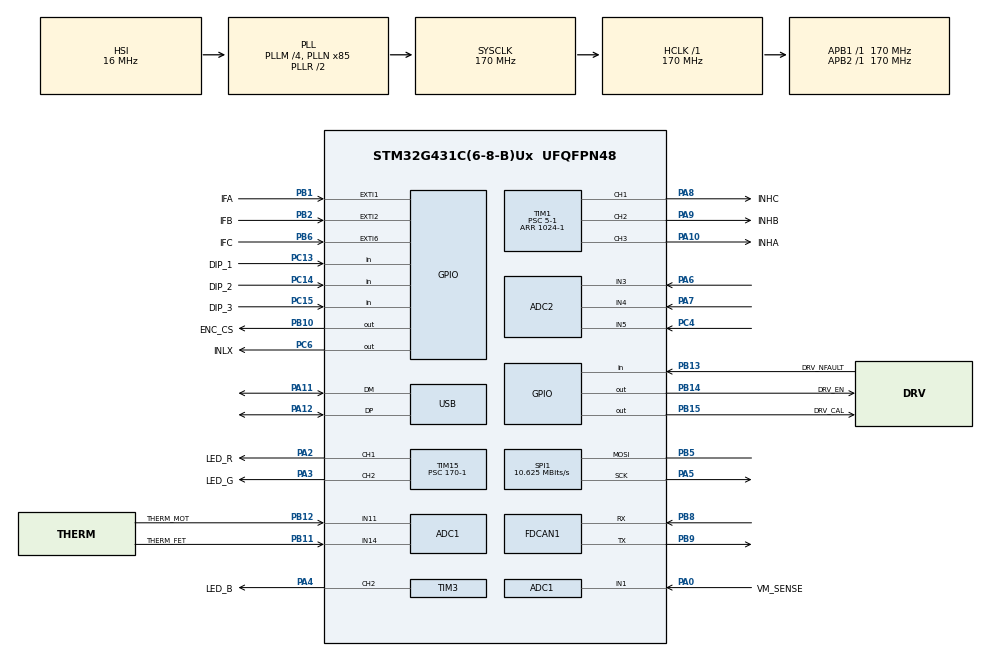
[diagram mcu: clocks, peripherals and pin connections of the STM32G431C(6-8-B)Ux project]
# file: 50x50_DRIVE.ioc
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ADC1.Channel-1\#ChannelRegularConversion=ADC_CHANNEL_1
ADC1.Channel-2\#ChannelRegularConversion=ADC_CHANNEL_TEMPSENSOR_ADC1
ADC1.Channel-3\#ChannelRegularConversion=ADC_CHANNEL_VREFINT
ADC1.Channel-4\#ChannelRegularConversion=ADC_CHANNEL_11
ADC1.Channel-5\#ChannelRegularConversion=ADC_CHANNEL_14
ADC1.ClockPrescaler=ADC_CLOCK_ASYNC_DIV16
ADC1.ContinuousConvMode=ENABLE
ADC1.DMAContinuousRequests=ENABLE
ADC1.NbrOfConversion=5
ADC1.NbrOfConversionFlag=1
ADC1.OffsetNumber-1\#ChannelRegularConversion=ADC_OFFSET_NONE
ADC1.OffsetNumber-2\#ChannelRegularConversion=ADC_OFFSET_NONE
ADC1.OffsetNumber-3\#ChannelRegularConversion=ADC_OFFSET_NONE
ADC1.OffsetNumber-4\#ChannelRegularConversion=ADC_OFFSET_NONE
ADC1.OffsetNumber-5\#ChannelRegularConversion=ADC_OFFSET_NONE
ADC1.OversamplingMode=DISABLE
ADC1.Rank-1\#ChannelRegularConversion=1
ADC1.Rank-2\#ChannelRegularConversion=2
ADC1.Rank-3\#ChannelRegularConversion=3
ADC1.Rank-4\#ChannelRegularConversion=4
ADC1.Rank-5\#ChannelRegularConversion=5
ADC1.SamplingTime-1\#ChannelRegularConversion=ADC_SAMPLETIME_247CYCLES_5
ADC1.SamplingTime-2\#ChannelRegularConversion=ADC_SAMPLETIME_92CYCLES_5
ADC1.SamplingTime-3\#ChannelRegularConversion=ADC_SAMPLETIME_92CYCLES_5
ADC1.SamplingTime-4\#ChannelRegularConversion=ADC_SAMPLETIME_92CYCLES_5
ADC1.SamplingTime-5\#ChannelRegularConversion=ADC_SAMPLETIME_92CYCLES_5
ADC1.master=1
ADC2.Channel-10\#ChannelRegularConversion=ADC_CHANNEL_5
ADC2.Channel-6\#ChannelRegularConversion=ADC_CHANNEL_3
ADC2.Channel-9\#ChannelRegularConversion=ADC_CHANNEL_4
ADC2.ClockPrescaler=ADC_CLOCK_ASYNC_DIV16
ADC2.ContinuousConvMode=DISABLE
ADC2.DMAContinuousRequests=ENABLE
ADC2.DataAlign=ADC_DATAALIGN_RIGHT
ADC2.DiscontinuousConvMode=DISABLE
ADC2.EOCSelection=ADC_EOC_SINGLE_CONV
ADC2.EnableInjectedConversion=DISABLE
ADC2.ExternalTrigConv=ADC_EXTERNALTRIG_T1_TRGO
ADC2.ExternalTrigConvEdge=ADC_EXTERNALTRIGCONVEDGE_RISING
ADC2.NbrOfConversion=3
ADC2.NbrOfConversionFlag=1
ADC2.OffsetNumber-10\#ChannelRegularConversion=ADC_OFFSET_NONE
ADC2.OffsetNumber-6\#ChannelRegularConversion=ADC_OFFSET_NONE
ADC2.OffsetNumber-9\#ChannelRegularConversion=ADC_OFFSET_NONE
ADC2.Overrun=ADC_OVR_DATA_PRESERVED
ADC2.Rank-10\#ChannelRegularConversion=3
ADC2.Rank-6\#ChannelRegularConversion=1
ADC2.Rank-9\#ChannelRegularConversion=2
ADC2.Rank1_Channel=ADC_CHANNEL_3
ADC2.Rank2_Channel=ADC_CHANNEL_3
ADC2.Rank3_Channel=ADC_CHANNEL_3
ADC2.SamplingTime-10\#ChannelRegularConversion=ADC_SAMPLETIME_12CYCLES_5
ADC2.SamplingTime-6\#ChannelRegularConversion=ADC_SAMPLETIME_24CYCLES_5
ADC2.SamplingTime-9\#ChannelRegularConversion=ADC_SAMPLETIME_24CYCLES_5
Dma.ADC1.0.Direction=DMA_PERIPH_TO_MEMORY
Dma.ADC1.0.EventEnable=DISABLE
Dma.ADC1.0.Instance=DMA1_Channel1
Dma.ADC1.0.MemDataAlignment=DMA_MDATAALIGN_HALFWORD
Dma.ADC1.0.MemInc=DMA_MINC_ENABLE
Dma.ADC1.0.Mode=DMA_CIRCULAR
Dma.ADC1.0.PeriphDataAlignment=DMA_PDATAALIGN_HALFWORD
Dma.ADC1.0.PeriphInc=DMA_PINC_DISABLE
Dma.ADC1.0.Polarity=HAL_DMAMUX_REQ_GEN_RISING
Dma.ADC1.0.Priority=DMA_PRIORITY_LOW
Dma.ADC1.0.RequestNumber=1
Dma.ADC1.0.SignalID=NONE
Dma.ADC1.0.SyncEnable=DISABLE
Dma.ADC1.0.SyncPolarity=HAL_DMAMUX_SYNC_NO_EVENT
Dma.ADC1.0.SyncRequestNumber=1
Dma.ADC1.0.SyncSignalID=NONE
Dma.ADC2.1.Direction=DMA_PERIPH_TO_MEMORY
Dma.ADC2.1.EventEnable=DISABLE
Dma.ADC2.1.Instance=DMA1_Channel2
Dma.ADC2.1.MemDataAlignment=DMA_MDATAALIGN_HALFWORD
Dma.ADC2.1.MemInc=DMA_MINC_ENABLE
Dma.ADC2.1.Mode=DMA_CIRCULAR
Dma.ADC2.1.PeriphDataAlignment=DMA_PDATAALIGN_HALFWORD
Dma.ADC2.1.PeriphInc=DMA_PINC_DISABLE
Dma.ADC2.1.Polarity=HAL_DMAMUX_REQ_GEN_RISING
Dma.ADC2.1.Priority=DMA_PRIORITY_HIGH
Dma.ADC2.1.RequestNumber=1
Dma.ADC2.1.SignalID=NONE
Dma.ADC2.1.SyncEnable=DISABLE
Dma.ADC2.1.SyncPolarity=HAL_DMAMUX_SYNC_NO_EVENT
Dma.ADC2.1.SyncRequestNumber=1
Dma.ADC2.1.SyncSignalID=NONE
Dma.Request0=ADC1
Dma.Request1=ADC2
FDCAN1.AutoRetransmission=ENABLE
FDCAN1.CalculateBaudRateNominal=999999
FDCAN1.CalculateTimeBitNominal=1000
FDCAN1.CalculateTimeQuantumNominal=58.82352941176471
FDCAN1.DataPrescaler=10
FDCAN1.DataTimeSeg1=14
FDCAN1.DataTimeSeg2=2
FDCAN1.FrameFormat=FDCAN_FRAME_FD_NO_BRS
FDCAN1.NominalPrescaler=10
FDCAN1.NominalTimeSeg1=14
FDCAN1.NominalTimeSeg2=2
FDCAN1.ProtocolException=ENABLE
FDCAN1.StdFiltersNbr=1
FDCAN1.TransmitPause=ENABLE
Mcu.Family=STM32G4
Mcu.Name=STM32G431C(6-8-B)Ux
Mcu.Package=UFQFPN48
NVIC.FDCAN1_IT0_IRQn=true\:0\:0\:true\:false\:true\:true\:true\:true
NVIC.PriorityGroup=NVIC_PRIORITYGROUP_4
NVIC.TIM1_TRG_COM_TIM17_IRQn=true\:0\:0\:true\:false\:true\:true\:true\:true
NVIC.TIM6_DAC_IRQn=true\:0\:0\:true\:false\:true\:true\:true\:true
NVIC.TimeBase=TIM1_TRG_COM_TIM17_IRQn
NVIC.TimeBaseIP=TIM17
NVIC.USB_LP_IRQn=true\:0\:0\:true\:false\:true\:false\:true\:true
PA0.GPIO_Label=VM_SENSE
PA0.Mode=IN1-Single-Ended
PA0.Signal=ADC1_IN1
PA10.GPIO_Label=INHA
PA10.Signal=S_TIM1_CH3
PA11.Mode=Device
PA11.Signal=USB_DM
PA12.Mode=Device
PA12.Signal=USB_DP
PA13.Mode=Trace_Asynchronous_SW
PA13.Signal=SYS_JTMS-SWDIO
PA14.Mode=Trace_Asynchronous_SW
PA14.Signal=SYS_JTCK-SWCLK
PA2.GPIO_Label=LED_R
PA2.Signal=S_TIM15_CH1
PA3.GPIO_Label=LED_G
PA3.Signal=S_TIM15_CH2
PA4.GPIO_Label=LED_B
PA4.Signal=S_TIM3_CH2
PA5.Mode=Simplex_Bidirectional_Master
PA5.Signal=SPI1_SCK
PA6.GPIO_Mode=GPIO_MODE_ANALOG
PA6.GPIO_PuPd=GPIO_NOPULL
PA6.Mode=IN3-Single-Ended
PA6.Signal=ADC2_IN3
PA7.GPIO_Mode=GPIO_MODE_ANALOG
PA7.GPIO_PuPd=GPIO_NOPULL
PA7.Mode=IN4-Single-Ended
PA7.Signal=ADC2_IN4
PA8.GPIO_Label=INHC
PA8.Signal=S_TIM1_CH1
PA9.GPIO_Label=INHB
PA9.Signal=S_TIM1_CH2
PB1.GPIO_Label=IFA
PB1.GPIO_ModeDefaultEXTI=GPIO_MODE_IT_RISING_FALLING
PB1.GPIO_PuPd=GPIO_NOPULL
PB1.Signal=GPXTI1
PB10.GPIO_Label=ENC_CS
PB10.Signal=GPIO_Output
PB11.GPIO_Label=THERM_FET
PB11.Mode=IN14-Single-Ended
PB11.Signal=ADC1_IN14
PB12.GPIO_Label=THERM_MOT
PB12.Mode=IN11-Single-Ended
PB12.Signal=ADC1_IN11
PB13.GPIO_Label=DRV_NFAULT
PB13.Signal=GPIO_Input
PB14.GPIO_Label=DRV_EN
PB14.Signal=GPIO_Output
PB15.GPIO_Label=DRV_CAL
PB15.Signal=GPIO_Output
PB2.GPIO_Label=IFB
PB2.GPIO_ModeDefaultEXTI=GPIO_MODE_IT_RISING_FALLING
PB2.GPIO_PuPd=GPIO_NOPULL
PB2.Signal=GPXTI2
PB3.Mode=Trace_Asynchronous_SW
PB3.Signal=SYS_JTDO-SWO
PB5.Mode=Simplex_Bidirectional_Master
PB5.Signal=SPI1_MOSI
PB6.GPIO_Label=IFC
PB6.Signal=GPXTI6
PB8-BOOT0.GPIO_FM8=SYSCFG_FASTMODEPLUS_PB8
PB8-BOOT0.GPIO_Speed=GPIO_SPEED_FREQ_VERY_HIGH
PB8-BOOT0.Mode=FDCAN_Activate
PB8-BOOT0.Signal=FDCAN1_RX
PB9.GPIO_FM9=SYSCFG_FASTMODEPLUS_PB9
PB9.GPIO_Speed=GPIO_SPEED_FREQ_VERY_HIGH
PB9.Mode=FDCAN_Activate
PB9.Signal=FDCAN1_TX
PC13.GPIO_Label=DIP_1
PC13.Signal=GPIO_Input
PC14-OSC32_IN.GPIO_Label=DIP_2
PC14-OSC32_IN.Signal=GPIO_Input
PC15-OSC32_OUT.GPIO_Label=DIP_3
PC15-OSC32_OUT.Signal=GPIO_Input
PC4.GPIO_Mode=GPIO_MODE_ANALOG
PC4.GPIO_PuPd=GPIO_NOPULL
PC4.Mode=IN5-Single-Ended
PC4.Signal=ADC2_IN5
PC6.GPIO_Label=INLX
PC6.Signal=GPIO_Output
ProjectManager.HeapSize=0x200
ProjectManager.StackSize=0x400
ProjectManager.TargetToolchain=Makefile
RCC.ADC12Freq_Value=170000000
RCC.AHBFreq_Value=170000000
RCC.APB1Freq_Value=170000000
RCC.APB1TimFreq_Value=170000000
RCC.APB2Freq_Value=170000000
RCC.APB2TimFreq_Value=170000000
RCC.CK48CLockSelection=RCC_USBCLKSOURCE_HSI48
RCC.CortexFreq_Value=170000000
RCC.EXTERNAL_CLOCK_VALUE=12288000
RCC.HCLKFreq_Value=170000000
RCC.HSE_VALUE=8000000
RCC.HSI48_VALUE=48000000
RCC.HSI_VALUE=16000000
RCC.LSE_VALUE=32768
RCC.PLLM=RCC_PLLM_DIV4
RCC.PLLN=85
RCC.PLLQ=RCC_PLLQ_DIV8
RCC.SYSCLKFreq_VALUE=170000000
RCC.SYSCLKSource=RCC_SYSCLKSOURCE_PLLCLK
RCC.USBFreq_Value=48000000
RCC.VCOOutputFreq_Value=340000000
SH.S_TIM15_CH1.0=TIM15_CH1,PWM Generation1 CH1
SH.S_TIM15_CH2.0=TIM15_CH2,PWM Generation2 CH2
SH.S_TIM1_CH1.0=TIM1_CH1,PWM Generation1 CH1
SH.S_TIM1_CH2.0=TIM1_CH2,PWM Generation2 CH2
SH.S_TIM1_CH3.0=TIM1_CH3,PWM Generation3 CH3
SH.S_TIM3_CH2.0=TIM3_CH2,PWM Generation2 CH2
SPI1.BaudRatePrescaler=SPI_BAUDRATEPRESCALER_16
SPI1.CLKPhase=SPI_PHASE_2EDGE
SPI1.CalculateBaudRate=10.625 MBits/s
SPI1.DataSize=SPI_DATASIZE_8BIT
SPI1.Direction=SPI_DIRECTION_1LINE
SPI1.Mode=SPI_MODE_MASTER
SPI1.VirtualType=VM_MASTER
TIM1.AutoReloadPreload=TIM_AUTORELOAD_PRELOAD_DISABLE
TIM1.Channel-Output\ Compare4\ No\ Output=TIM_CHANNEL_4
TIM1.Channel-PWM\ Generation1\ CH1=TIM_CHANNEL_1
TIM1.Channel-PWM\ Generation2\ CH2=TIM_CHANNEL_2
TIM1.Channel-PWM\ Generation3\ CH3=TIM_CHANNEL_3
TIM1.CounterMode=TIM_COUNTERMODE_CENTERALIGNED3
TIM1.OCFastMode_PWM-PWM\ Generation1\ CH1=TIM_OCFAST_DISABLE
TIM1.OCFastMode_PWM-PWM\ Generation2\ CH2=TIM_OCFAST_DISABLE
TIM1.OCFastMode_PWM-PWM\ Generation3\ CH3=TIM_OCFAST_DISABLE
TIM1.OCMode_4=TIM_OCMODE_DIRECTION_OUTPUT
TIM1.OCPolarity_1=TIM_OCPOLARITY_HIGH
TIM1.OCPolarity_2=TIM_OCPOLARITY_HIGH
TIM1.OCPolarity_3=TIM_OCPOLARITY_HIGH
TIM1.PeriodNoDither=1024-1
TIM1.Prescaler=5-1
TIM1.TIM_MasterOutputTrigger=TIM_TRGO_OC4REF
TIM1.TIM_MasterOutputTrigger2=TIM_TRGO2_OC1REF
TIM1.TIM_MasterSlaveMode=TIM_MASTERSLAVEMODE_DISABLE
TIM15.Channel-PWM\ Generation1\ CH1=TIM_CHANNEL_1
TIM15.Channel-PWM\ Generation2\ CH2=TIM_CHANNEL_2
TIM15.OCIdleState_1=TIM_OCIDLESTATE_SET
TIM15.OCIdleState_2=TIM_OCIDLESTATE_SET
TIM15.OCPolarity_1=TIM_OCPOLARITY_LOW
TIM15.OCPolarity_2=TIM_OCPOLARITY_LOW
TIM15.PeriodNoDither=1000-1
TIM15.Prescaler=170-1
TIM2.Prescaler=170-1
TIM3.Channel-PWM\ Generation2\ CH2=TIM_CHANNEL_2
TIM3.OCPolarity_2=TIM_OCPOLARITY_LOW
TIM3.PeriodNoDither=1000
TIM3.Prescaler=170-1
TIM6.PeriodNoDither=100-1
TIM6.Prescaler=170-1
USB.Sof_enable=ENABLE
USB_DEVICE.CLASS_NAME_FS=CDC
USB_DEVICE.MANUFACTURER_STRING=Daisy
USB_DEVICE.PRODUCT_STRING_CDC_FS=50x50-Drive
USB_DEVICE.USBD_DEBUG_LEVEL=1
USB_DEVICE.USBD_SELF_POWERED=0
USB_DEVICE.VirtualMode=Cdc
USB_DEVICE.VirtualModeFS=Cdc_FS
VP_ADC1_TempSens_Input.Mode=IN-TempSens
VP_ADC1_Vref_Input.Mode=IN-Vrefint
VP_RTC_VS_RTC_Activate.Mode=RTC_Enabled
VP_SYS_VS_DBSignals.Mode=DisableDeadBatterySignals
VP_SYS_VS_tim17.Mode=TIM17
VP_TIM1_VS_ClockSourceINT.Mode=Internal
VP_TIM1_VS_no_output4.Mode=Output Compare4 No Output
VP_TIM2_VS_ClockSourceINT.Mode=Internal
VP_TIM3_VS_ClockSourceINT.Mode=Internal
VP_TIM6_VS_ClockSourceINT.Mode=Enable_Timer
VP_USB_DEVICE_VS_USB_DEVICE_CDC_FS.Mode=CDC_FS
board=custom

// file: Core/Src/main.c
/* USER CODE BEGIN Header */
/**
  ******************************************************************************
  * @file           : main.c
  * @brief          : Main program body
  ******************************************************************************
  * @attention
  *
  * Copyright (c) 2026 STMicroelectronics.
  * All rights reserved.
  *
  * This software is licensed under terms that can be found in the LICENSE file
  * in the root directory of this software component.
  * If no LICENSE file comes with this software, it is provided AS-IS.
  *
  ******************************************************************************
  */
/* USER CODE END Header */
#include "main.h"
#include "adc.h"
#include "dma.h"
#include "fdcan.h"
#include "rtc.h"
#include "spi.h"
#include "tim.h"
#include "usb_device.h"
#include "gpio.h"

/* USER CODE BEGIN Includes */
#include "app_main.h"
/* USER CODE END Includes */

void SystemClock_Config(void);

int main(void)
{

  /* MCU Configuration--------------------------------------------------------*/

  /* Reset of all peripherals, Initializes the Flash interface and the Systick. */
  HAL_Init();

  /* Configure the system clock */
  SystemClock_Config();

  /* Initialize all configured peripherals */
  MX_GPIO_Init();
  MX_DMA_Init();
  MX_ADC1_Init();
  MX_ADC2_Init();
  MX_TIM1_Init();
  MX_USB_Device_Init();
  MX_TIM3_Init();
  MX_TIM15_Init();
  MX_TIM6_Init();
  MX_FDCAN1_Init();
  MX_RTC_Init();
  MX_TIM2_Init();
  MX_SPI1_Init();
  /* USER CODE BEGIN 2 */
  app_main();
  /* USER CODE END 2 */

  /* Infinite loop */
  while (1)
  {

  }
}

void SystemClock_Config(void)
{
  RCC_OscInitTypeDef RCC_OscInitStruct = {0};
  RCC_ClkInitTypeDef RCC_ClkInitStruct = {0};

  /** Configure the main internal regulator output voltage
  */
  HAL_PWREx_ControlVoltageScaling(PWR_REGULATOR_VOLTAGE_SCALE1_BOOST);

  /** Initializes the RCC Oscillators according to the specified parameters
  * in the RCC_OscInitTypeDef structure.
  */
  RCC_OscInitStruct.OscillatorType = RCC_OSCILLATORTYPE_HSI|RCC_OSCILLATORTYPE_HSI48
                              |RCC_OSCILLATORTYPE_LSI;
  RCC_OscInitStruct.HSIState = RCC_HSI_ON;
  RCC_OscInitStruct.HSICalibrationValue = RCC_HSICALIBRATION_DEFAULT;
  RCC_OscInitStruct.LSIState = RCC_LSI_ON;
  RCC_OscInitStruct.HSI48State = RCC_HSI48_ON;
  RCC_OscInitStruct.PLL.PLLState = RCC_PLL_ON;
  RCC_OscInitStruct.PLL.PLLSource = RCC_PLLSOURCE_HSI;
  RCC_OscInitStruct.PLL.PLLM = RCC_PLLM_DIV4;
  RCC_OscInitStruct.PLL.PLLN = 85;
  RCC_OscInitStruct.PLL.PLLP = RCC_PLLP_DIV2;
  RCC_OscInitStruct.PLL.PLLQ = RCC_PLLQ_DIV8;
  RCC_OscInitStruct.PLL.PLLR = RCC_PLLR_DIV2;
  if (HAL_RCC_OscConfig(&RCC_OscInitStruct) != HAL_OK)
  {
    Error_Handler();
  }

  /** Initializes the CPU, AHB and APB buses clocks
  */
  RCC_ClkInitStruct.ClockType = RCC_CLOCKTYPE_HCLK|RCC_CLOCKTYPE_SYSCLK
                              |RCC_CLOCKTYPE_PCLK1|RCC_CLOCKTYPE_PCLK2;
  RCC_ClkInitStruct.SYSCLKSource = RCC_SYSCLKSOURCE_PLLCLK;
  RCC_ClkInitStruct.AHBCLKDivider = RCC_SYSCLK_DIV1;
  RCC_ClkInitStruct.APB1CLKDivider = RCC_HCLK_DIV1;
  RCC_ClkInitStruct.APB2CLKDivider = RCC_HCLK_DIV1;

  if (HAL_RCC_ClockConfig(&RCC_ClkInitStruct, FLASH_LATENCY_4) != HAL_OK)
  {
    Error_Handler();
  }
}

void HAL_TIM_PeriodElapsedCallback(TIM_HandleTypeDef *htim)
{
  /* USER CODE BEGIN Callback 0 */
  tim_elapsed_callback(htim);
  /* USER CODE END Callback 0 */
  if (htim->Instance == TIM17)
  {
    HAL_IncTick();
  }
}

void Error_Handler(void)
{
  __disable_irq();
  while (1)
  {
  }
}
